# MCAN0_CFG register map
Vendor: Texas Instruments
Peripheral module from a debugger description file (folder J7VCL).
Registers are 32-bit, access per field, reset 0x0 unless marked. A register's access mark holds for its fields unless they carry their own. Offsets are as the file gives them; lines under a group give offsets from that group; [hi:lo] are bit positions; {n}, {i} and the like mark numbered series; 'fields as' and 'values as' point back to an identical list; <NAME> marks a mode.

## MCAN0_CFG (part 1 of 2)
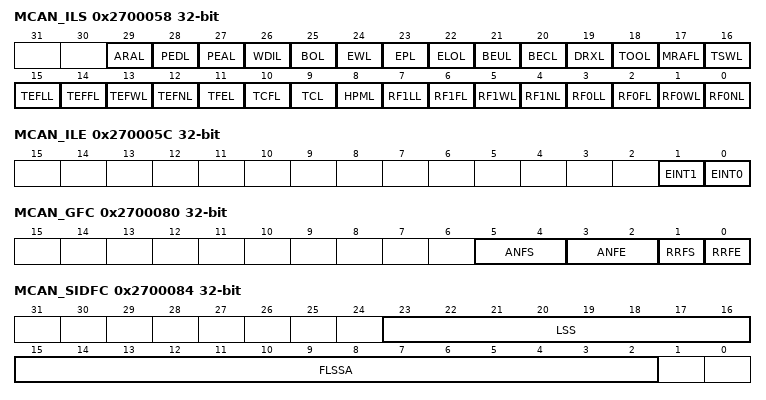
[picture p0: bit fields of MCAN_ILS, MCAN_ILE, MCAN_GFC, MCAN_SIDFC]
0x2700058 MCAN_ILS — Interrupt Line Select The Interrupt Line Select register assigns an interrupt generated by a specific interrupt flag from the register to one of the two module interrupt lines. For interrupt generation the respective interrupt line has to be enabled via the [0] EINT0 and [1] EINT1 bits.
  [29] ARAL rw — Access to Reserved Address Line 0h = Interrupt assigned to interrupt line INT0 1h = Interrupt assigned to interrupt line INT1
  [28] PEDL rw — Protocol Error in Data Phase Line 0h = Interrupt assigned to interrupt line INT0 1h = Interrupt assigned to interrupt line INT1
  [27] PEAL rw — Protocol Error in Arbitration Phase Line 0h = Interrupt assigned to interrupt line INT0 1h = Interrupt assigned to interrupt line INT1
  [26] WDIL rw — Watchdog Interrupt Line 0h = Interrupt assigned to interrupt line INT0 1h = Interrupt assigned to interrupt line INT1
  [25] BOL rw — Bus_Off Status Interrupt Line 0h = Interrupt assigned to interrupt line INT0 1h = Interrupt assigned to interrupt line INT1
  [24] EWL rw — Warning Status Interrupt Line 0h = Interrupt assigned to interrupt line INT0 1h = Interrupt assigned to interrupt line INT1
  [23] EPL rw — Error Passive Interrupt Line 0h = Interrupt assigned to interrupt line INT0 1h = Interrupt assigned to interrupt line INT1
  [22] ELOL rw — Error Logging Overflow Interrupt Line 0h = Interrupt assigned to interrupt line INT0 1h = Interrupt assigned to interrupt line INT1
  [21] BEUL rw — Bit Error Uncorrected Interrupt Line 0h = Interrupt assigned to interrupt line INT0 1h = Interrupt assigned to interrupt line INT1
  [20] BECL rw — Bit Error Corrected Interrupt Line 0h = Interrupt assigned to interrupt line INT0 1h = Interrupt assigned to interrupt line INT1
  [19] DRXL rw — Message stored to Dedicated Rx Buffer Interrupt Line 0h = Interrupt assigned to interrupt line INT0 1h = Interrupt assigned to interrupt line INT1
  [18] TOOL rw — Timeout Occurred Interrupt Line 0h = Interrupt assigned to interrupt line INT0 1h = Interrupt assigned to interrupt line INT1
  [17] MRAFL rw — Message RAM Access Failure Interrupt Line 0h = Interrupt assigned to interrupt line INT0 1h = Interrupt assigned to interrupt line INT1
  [16] TSWL rw — Timestamp Wraparound Interrupt Line 0h = Interrupt assigned to interrupt line INT0 1h = Interrupt assigned to interrupt line INT1
  [15] TEFLL rw — Tx Event FIFO Event Lost Interrupt Line 0h = Interrupt assigned to interrupt line INT0 1h = Interrupt assigned to interrupt line INT1
  [14] TEFFL rw — Tx Event FIFO Full Interrupt Line 0h = Interrupt assigned to interrupt line INT0 1h = Interrupt assigned to interrupt line INT1
  [13] TEFWL rw — Tx Event FIFO Watermark Reached Interrupt Line 0h = Interrupt assigned to interrupt line INT0 1h = Interrupt assigned to interrupt line INT1
  [12] TEFNL rw — Tx Event FIFO New Entry Interrupt Line 0h = Interrupt assigned to interrupt line INT0 1h = Interrupt assigned to interrupt line INT1
  [11] TFEL rw — Tx FIFO Empty Interrupt Line 0h = Interrupt assigned to interrupt line INT0 1h = Interrupt assigned to interrupt line INT1
  [10] TCFL rw — Transmission Cancellation Finished Interrupt Line 0h = Interrupt assigned to interrupt line INT0 1h = Interrupt assigned to interrupt line INT1
  [9] TCL rw — Transmission Completed Interrupt Line 0h = Interrupt assigned to interrupt line INT0 1h = Interrupt assigned to interrupt line INT1
  [8] HPML rw — High Priority Message Interrupt Line 0h = Interrupt assigned to interrupt line INT0 1h = Interrupt assigned to interrupt line INT1
  [7] RF1LL rw — Rx FIFO 1 Message Lost Interrupt Line 0h = Interrupt assigned to interrupt line INT0 1h = Interrupt assigned to interrupt line INT1
  [6] RF1FL rw — Rx FIFO 1 Full Interrupt Line 0h = Interrupt assigned to interrupt line INT0 1h = Interrupt assigned to interrupt line INT1
  [5] RF1WL rw — Rx FIFO 1 Watermark Reached Interrupt Line 0h = Interrupt assigned to interrupt line INT0 1h = Interrupt assigned to interrupt line INT1
  [4] RF1NL rw — Rx FIFO 1 New Message Interrupt Line 0h = Interrupt assigned to interrupt line INT0 1h = Interrupt assigned to interrupt line INT1
  [3] RF0LL rw — Rx FIFO 0 Message Lost Interrupt Line 0h = Interrupt assigned to interrupt line INT0 1h = Interrupt assigned to interrupt line INT1
  [2] RF0FL rw — Rx FIFO 0 Full Interrupt Line 0h = Interrupt assigned to interrupt line INT0 1h = Interrupt assigned to interrupt line INT1
  [1] RF0WL rw — Rx FIFO 0 Watermark Reached Interrupt Line 0h = Interrupt assigned to interrupt line INT0 1h = Interrupt assigned to interrupt line INT1
  [0] RF0NL rw — Rx FIFO 0 New Message Interrupt Line 0h = Interrupt assigned to interrupt line INT0 1h = Interrupt assigned to interrupt line INT1
0x270005C MCAN_ILE — Interrupt Line Enable Enable/disable interrupt lines INT0/INT1. Each of the two interrupt lines to the Host CPU can be enabled/disabled separately by programming the [0] EINT0 and [1] EINT1 bits.
  [1] EINT1 rw — Enable Interrupt Line 1 0h = Interrupt line INT1 disabled 1h = Interrupt line INT1 enabled
  [0] EINT0 rw — Enable Interrupt Line 0 0h = Interrupt line INT0 disabled 1h = Interrupt line INT0 enabled
0x2700080 MCAN_GFC — Global Filter Configuration Handling of non-matching frames and remote frames. Global settings for Message ID filtering. The register controls the filter path for standard and extended messages (see and ).
  [5:4] ANFS rw — Accept Non-matching Frames Standard Defines how received messages with 11-bit IDs that do not match any element of the filter list are treated. 0h = Accept in Rx FIFO 0 1h = Accept in Rx FIFO 1 2h = Reject 3h = Reject
  [3:2] ANFE rw — Accept Non-matching Frames Extended Defines how received messages with 29-bit IDs that do not match any element of the filter list are treated. 0h = Accept in Rx FIFO 0 1h = Accept in Rx FIFO 1 2h = Reject 3h = Reject
  [1] RRFS rw — Reject Remote Frames Standard 0h = Filter remote frames with 11-bit standard IDs 1h = Reject all remote frames with 11-bit standard IDs
  [0] RRFE rw — Reject Remote Frames Extended 0h = Filter remote frames with 29-bit extended IDs 1h = Reject all remote frames with 29-bit extended IDs
0x2700084 MCAN_SIDFC — Standard ID Filter Configuration Number of filter elements, pointer to start of filter list. Settings for 11-bit standard Message ID filtering. The Standard ID Filter Configuration controls the filter path for standard messages (see ).
  [23:16] LSS rw — List Size Standard 0h = No standard Message ID filter 1h-80h (1-128) = Number of standard Message ID filter elements &gt; 80h (128) = Values greater than 128 are interpreted as 128
  [15:2] FLSSA rw — Filter List Standard Start Address Start address of standard Message ID filter list (32-bit word address, see
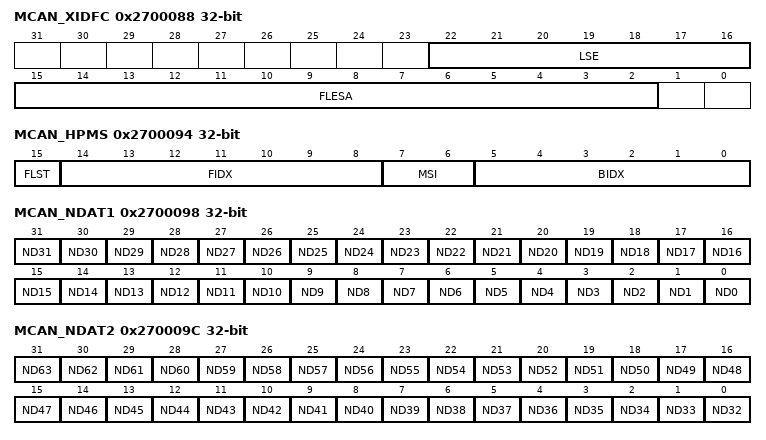
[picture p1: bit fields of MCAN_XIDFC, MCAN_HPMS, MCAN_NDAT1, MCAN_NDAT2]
0x2700088 MCAN_XIDFC — Extended ID Filter Configuration Number of filter elements, pointer to start of filter list. Settings for 29-bit extended Message ID filtering. The Extended ID Filter Configuration controls the filter path for standard messages (see ).
  [22:16] LSE rw — List Size Extended 0h = No extended Message ID filter 1h-40h (1-64) = Number of extended Message ID filter elements &gt; 40h (64) = Values greater than 64 are interpreted as 64
  [15:2] FLESA rw — Filter List Extended Start Address Start address of extended Message ID filter list (32-bit word address, see
0x2700090 MCAN_XIDAM reset 0x1FFFFFFF — Extended ID AND Mask 29-bit logical AND mask for J1939.
  [28:0] EIDM rw — Extended ID Mask For acceptance filtering of extended frames the Extended ID AND Mask is ANDed with the Message ID of a received frame. Intended for masking of 29-bit IDs in SAE J1939. With the reset value of all bits set to one the mask is not active.
0x2700094 MCAN_HPMS ro — High Priority Message Status Status monitoring of incoming high priority messages. This register is updated every time a Message ID filter element configured to generate a priority event matches. This can be used to monitor the status of incoming high priority messages and to enable fast access to these messages.
  [15] FLST — Filter List Indicates the filter list of the matching filter element. 0h = Standard Filter List 1h = Extended Filter List
  [14:8] FIDX — Filter Index Index of matching filter element. Range is 0 to
  [7:6] MSI — Message Storage Indicator 0h = No FIFO selected 1h = FIFO message lost 2h = Message stored in FIFO 0 3h = Message stored in FIFO 1
  [5:0] BIDX — Buffer Index Index of Rx FIFO element to which the message was stored. Only valid when the
0x2700098 MCAN_NDAT1 access not given — New Data 1 NewDat flags of dedicated Rx buffers 0-31. The register holds the New Data flags of Rx Buffers 0 to 31. The flags are set when the respective Rx Buffer has been updated from a received frame. The flags remain set until the Host CPU clears them. Aflag is cleared by writing a 1h to the corresponding bit position. Writing a 0h has no effect. A hard reset will clear the register.
  [n] ND{n} (n=0..31) — New Data 0h = Rx Buffer not updated 1h = Rx Buffer updated from new message (access RW1TC)
0x270009C MCAN_NDAT2 access not given — New Data 2 NewDat flags of dedicated Rx buffers 32-63. The register holds the New Data flags of Rx Buffers 32 to 63. The flags are set when the respective Rx Buffer has been updated from a received frame. The flags remain set until the Host CPU clears them. A flag is cleared by writing a 1h to the corresponding bit position. Writing a 0h has no effect. A hard reset will clear the register.
  [n-32] ND{n} (n=32..63) — New Data 0h = Rx Buffer not updated 1h = Rx Buffer updated from new message (access RW1TC)
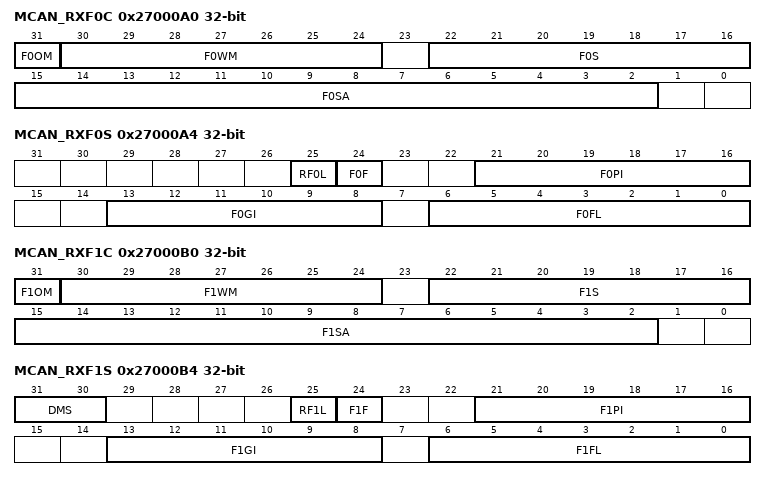
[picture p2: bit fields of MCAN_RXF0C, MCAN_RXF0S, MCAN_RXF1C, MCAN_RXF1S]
0x27000A0 MCAN_RXF0C — Rx FIFO 0 Configuration FIFO 0 operation mode, watermark, size and start address.
  [31] F0OM rw — FIFO 0 Operation Mode FIFO 0 can be operated in blocking or in overwrite mode (see 0h = FIFO 0 blocking mode 1h = FIFO 0 overwrite mode
  [30:24] F0WM rw — Rx FIFO 0 Watermark 0h = Watermark interrupt disabled 1h-40h (1-64) = Level for Rx FIFO 0 watermark interrupt ( &gt; 40h (64) = Watermark interrupt disabled
  [22:16] F0S rw — Rx FIFO 0 Size 0h = No Rx FIFO 0 1h-40h (1-64) = Number of Rx FIFO 0 elements &gt; 40h (64) = Values greater than 64 are interpreted as 64 The Rx FIFO 0 elements are indexed from 0 to
  [15:2] F0SA rw — Rx FIFO 0 Start Address Start address of Rx FIFO 0 in Message RAM (32-bit word address, see
0x27000A4 MCAN_RXF0S ro — Rx FIFO 0 Status FIFO 0 message lost/full indication, put index, get index and fill level.
  [25] RF0L — Rx FIFO 0 Message Lost This bit is a copy of interrupt flag 0h = No Rx FIFO 0 message lost 1h = Rx FIFO 0 message lost, also set after write attempt to Rx FIFO 0 of size zero Note:Overwriting the oldest message when the MCAN_RXF0C[31] F0OM = 1h will not set this flag.
  [24] F0F — Rx FIFO 0 Full 0h = Rx FIFO 0 not full 1h = Rx FIFO 0 full
  [21:16] F0PI — Rx FIFO 0 Put Index Rx FIFO 0 write index pointer, range 0 to 63.
  [13:8] F0GI — Rx FIFO 0 Get Index Rx FIFO 0 read index pointer, range 0 to 63.
  [6:0] F0FL — Rx FIFO 0 Fill Level Number of elements stored in Rx FIFO 0, range 0 to 64.
0x27000A8 MCAN_RXF0A — Rx FIFO 0 Acknowledge FIFO 0 acknowledge last index of read buffers, updates get index and fill level.
  [5:0] F0AI rw — Rx FIFO 0 Acknowledge Index After the Host CPU has read a message or a sequence of messages from Rx FIFO 0 it has to write the buffer index of the last element read from Rx FIFO 0 to the
0x27000AC MCAN_RXBC — Rx Buffer Configuration Start address of Rx buffer section.
  [15:2] RBSA rw — Rx Buffer Start Address Configures the start address of the Rx Buffers section in the Message RAM (32-bit word address, see ). Also used to reference debug messages A, B, C. Note:Debug feature is not supported.
0x27000B0 MCAN_RXF1C — Rx FIFO 1 Configuration FIFO 1 operation mode, watermark, size and start address.
  [31] F1OM rw — FIFO 1 Operation Mode FIFO 1 can be operated in blocking or in overwrite mode (see 0h = FIFO 1 blocking mode 1h = FIFO 1 overwrite mode
  [30:24] F1WM rw — Rx FIFO 1 Watermark 0h = Watermark interrupt disabled 1h-40h (1-64) = Level for Rx FIFO 1 watermark interrupt ( &gt; 40h (64) = Watermark interrupt disabled
  [22:16] F1S rw — Rx FIFO 1 Size 0h = No Rx FIFO 1 1h-40h (1-64) = Number of Rx FIFO 1 elements &gt; 40h (64) = Values greater than 64 are interpreted as 64 The Rx FIFO 1 elements are indexed from 0 to
  [15:2] F1SA rw — Rx FIFO 1 Start Address Start address of Rx FIFO 1 in Message RAM (32-bit word address, see
0x27000B4 MCAN_RXF1S ro — Rx FIFO 1 Status FIFO 1 message lost/full indication, put index, get index and fill level.
  [31:30] DMS — Debug Message Status 0h = Idle state, wait for reception of debug messages, DMA request is cleared 1h = Debug message A received 2h = Debug messages A, B received 3h = Debug messages A, B, C received, DMA request is set Note:Debug feature is not supported.
  [25] RF1L — Rx FIFO 1 Message Lost This bit is a copy of interrupt flag 0h = No Rx FIFO 1 message lost 1h = Rx FIFO 1 message lost, also set after write attempt to Rx FIFO 1 of size zero Note:Overwriting the oldest message when the MCAN_RXF1C[31] F1OM = 1h will not set this flag.
  [24] F1F — Rx FIFO 1 Full 0h = Rx FIFO 1 not full 1h = Rx FIFO 1 full
  [21:16] F1PI — Rx FIFO 1 Put Index Rx FIFO 1 write index pointer, range 0 to 63.
  [13:8] F1GI — Rx FIFO 1 Get Index Rx FIFO 1 read index pointer, range 0 to 63.
  [6:0] F1FL — Rx FIFO 1 Fill Level Number of elements stored in Rx FIFO 1, range 0 to 64.
0x27000B8 MCAN_RXF1A — Rx FIFO 1 Acknowledge FIFO 1 acknowledge last index of read buffers, updates get index and fill level.
  [5:0] F1AI rw — Rx FIFO 1 Acknowledge Index After the Host CPU has read a message or a sequence of messages from Rx FIFO 1 it has to write the buffer index of the last element read from Rx FIFO 1 to the
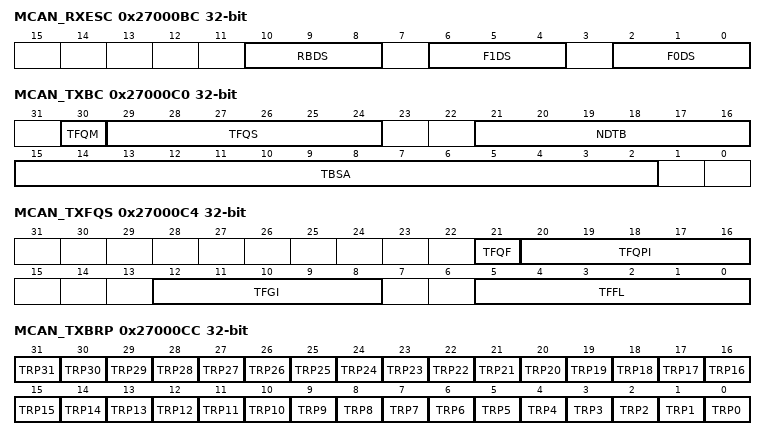
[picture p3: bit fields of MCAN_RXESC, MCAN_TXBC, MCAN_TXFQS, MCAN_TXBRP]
0x27000BC MCAN_RXESC — Rx Buffer/FIFO Element Size Configuration Configure data field size for storage of accepted frames.
  [10:8] RBDS rw — Rx Buffer Data Field Size 0h = 8 byte data field 1h = 12 byte data field 2h = 16 byte data field 3h = 20 byte data field 4h = 24 byte data field 5h = 32 byte data field 6h = 48 byte data field 7h = 64 byte data field
  [6:4] F1DS rw — Rx FIFO 1 Data Field Size 0h = 8 byte data field 1h = 12 byte data field 2h = 16 byte data field 3h = 20 byte data field 4h = 24 byte data field 5h = 32 byte data field 6h = 48 byte data field 7h = 64 byte data field
  [2:0] F0DS rw — Rx FIFO 0 Data Field Size 0h = 8 byte data field 1h = 12 byte data field 2h = 16 byte data field 3h = 20 byte data field 4h = 24 byte data field 5h = 32 byte data field 6h = 48 byte data field 7h = 64 byte data field Note:In case the data field size of an accepted CAN frame exceeds the data field size configured for the matching Rx Buffer or Rx FIFO, only the number of bytes as configured by the MCAN_RXESC register are stored to the Rx Buffer respectively Rx FIFO element. The rest of the frame's data field is ignored.
0x27000C0 MCAN_TXBC — Tx Buffer Configuration Configure Tx FIFO/Queue mode, Tx FIFO/Queue size, number of dedicated Tx buffers, Tx buffer start address.
  [30] TFQM rw — Tx FIFO/Queue Mode 0h = Tx FIFO operation 1h = Tx Queue operation
  [29:24] TFQS rw — Transmit FIFO/Queue Size 0h = No Tx FIFO/Queue 1h-20h (1-32) = Number of Tx Buffers used for Tx FIFO/Queue &gt; 20h (32) = Values greater than 32 are interpreted as 32
  [21:16] NDTB rw — Number of Dedicated Transmit Buffers 0h = No Dedicated Tx Buffers 1h-20h (1-32) = Number of Dedicated Tx Buffers &gt; 20h (32) = Values greater than 32 are interpreted as 32
  [15:2] TBSA rw — Tx Buffers Start Address Start address of Tx Buffers section in Message RAM (32-bit word address, see Note:Be aware that the sum of the MCAN_TXBC[29-24] TFQS and MCAN_TXBC[21-16] NDTB fields may be not greater than 32. There is no check for erroneous configurations. The Tx Buffers section in the Message RAM starts with the dedicated Tx Buffers.
0x27000C4 MCAN_TXFQS ro — Tx FIFO/Queue Status Tx FIFO/Queue full indication and put index, Tx FIFO get index and fill level. The Tx FIFO/Queue status is related to the pending Tx requests listed in the register. Therefore the effect of Add/Cancellation requests may be delayed due to a running Tx scan (the register not yet updated).
  [21] TFQF — Tx FIFO/Queue Full 0h = Tx FIFO/Queue not full 1h = Tx FIFO/Queue full
  [20:16] TFQPI — Tx FIFO/Queue Put Index Tx FIFO/Queue write index pointer, range 0 to 31.
  [12:8] TFGI — Tx FIFO Get Index Tx FIFO read index pointer, range 0 to 31. Read as zero when Tx Queue operation is configured (
  [5:0] TFFL — Tx FIFO Free Level Number of consecutive free Tx FIFO elements starting from the Note:In case of mixed configurations where dedicated Tx Buffers are combined with a Tx FIFO or a Tx Queue, the Put and Get Indices indicate the number of the Tx Buffer starting with the first dedicated Tx Buffers.
0x27000C8 MCAN_TXESC — Tx Buffer Element Size Configuration Configure data field size for frame transmission. Configures the number of data bytes belonging to a Tx Buffer element. Data field sizes > 8 bytes are intended for CAN FD operation only.
  [2:0] TBDS rw — Tx Buffer Data Field Size 0h = 8 byte data field 1h = 12 byte data field 2h = 16 byte data field 3h = 20 byte data field 4h = 24 byte data field 5h = 32 byte data field 6h = 48 byte data field 7h = 64 byte data field Note:In case the data length code DLC of a Tx Buffer element is configured to a value higher than the Tx Buffer data field size MCAN_TXESC[2-0] TBDS, the bytes not defined by the Tx Buffer are transmitted as CCh (padding bytes).
0x27000CC MCAN_TXBRP ro — Tx Buffer Request Pending Tx buffers with pending transmission request. Each Tx Buffer has its own Transmission Request Pending bit. The bits are set via the register. The bits are reset after a requested transmission has completed or has been cancelled via the register. The bits are set only for those Tx Buffers configured via the register. After a bit has been set, a Tx scan (see , Tx Handling) is started to check for the pending Tx request with the highest priority (Tx Buffer with lowest Message ID). A cancellation request resets the corresponding transmission request pending bit of register the register. In case a transmission has already been started when a cancellation is requested, this is done at the end of the transmission, regardless whether the transmission was successful or not. The cancellation request bits are reset directly after the corresponding bit has been reset. After a cancellation has been requested, a finished cancellation is signalled via the flag • after successful transmission together with the corresponding bit • when the transmission has not yet been started at the point of cancellation • when the transmission has been aborted due to lost arbitration • when an error occurred during frame transmission In DAR mode all transmissions are automatically cancelled if they are not successful. The corresponding bit is set for all unsuccessful transmissions. Note: The bits which are set while a Tx scan is in progress are not considered during this particular Tx scan. In case a cancellation is requested for such a Tx Buffer, this Add Request is cancelled immediately, the corresponding bit is reset.
  [n] TRP{n} (n=0..31) — Transmission Request Pending 0h = No transmission request pending 1h = Transmission request pending
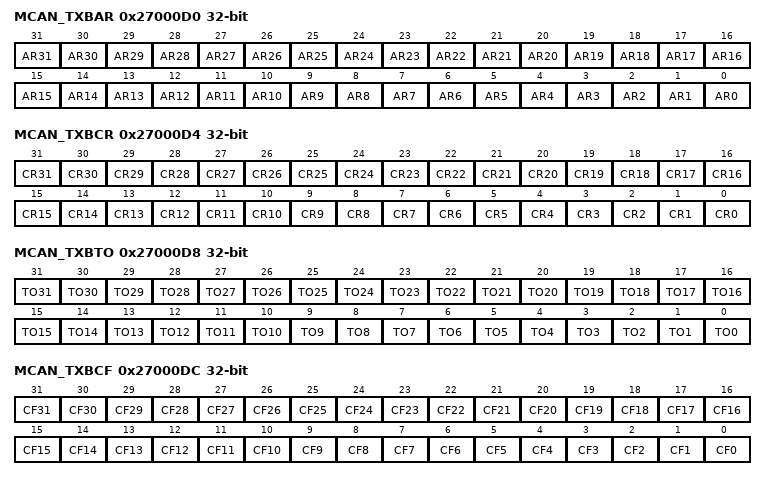
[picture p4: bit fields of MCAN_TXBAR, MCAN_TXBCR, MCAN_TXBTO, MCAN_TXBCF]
0x27000D0 MCAN_TXBAR access not given — Tx Buffer Add Request Add transmission requests. Each Tx Buffer has its own Add Request bit. Writing 1h will set the corresponding Add Request bit; writing a 0h has no impact. This enables the Host CPU to set transmission requests for multiple Tx Buffers with one write to the register. The bits are set only for those Tx Buffers configured via the register. When no Tx scan is running, the bits are reset immediately, else the bits remain set until the Tx scan process has completed. Note: If an add request is applied for a Tx Buffer with pending transmission request (corresponding bit already set), this add request is ignored.
  [n] AR{n} (n=0..31) — Add Request 0h = No transmission request added 1h = Transmission requested added (access RW1TC)
0x27000D4 MCAN_TXBCR access not given — Tx Buffer Cancellation Request Request cancellation of pending transmissions. Each Tx Buffer has its own Cancellation Request bit. Writing a 1h will set the corresponding Cancellation Request bit; writing a 0h has no impact. This enables the Host CPU to set cancellation requests for multiple Tx Buffers with one write to the register. The bits are set only for those Tx Buffers configured via the register. The bits remain set until the corresponding bit of the register is reset.
  [n] CR{n} (n=0..31) — Cancellation Request 0h = No cancellation pending 1h = Cancellation pending (access RW1TC)
0x27000D8 MCAN_TXBTO ro — Tx Buffer Transmission Occurred Signals successful transmissions, set when corresponding flag is cleared. Each Tx Buffer has its own Transmission Occurred bit. The bits are set when the corresponding bit is cleared after a successful transmission. The bits are reset when a new transmission is requested by writing a 1h to the corresponding bit of register the register.
  [n] TO{n} (n=0..31) — Transmission Occurred 0h = No transmission occurred 1h = Transmission occurred
0x27000DC MCAN_TXBCF ro — Tx Buffer Cancellation Finished Signals successful transmit cancellation, set when corresponding flag is cleared after cancellation request. Each Tx Buffer has its own Cancellation Finished bit. The bits are set when the corresponding bit is cleared after a cancellation was requested via the register. In case the corresponding bit was not set at the point of cancellation, [n] CF bit is set immediately. The bits are reset when a new transmission is requested by writing a 1h to the corresponding bit of the register.
  [n] CF{n} (n=0..31) — Cancellation Finished 0h = No transmit buffer cancellation 1h = Transmit buffer cancellation finished
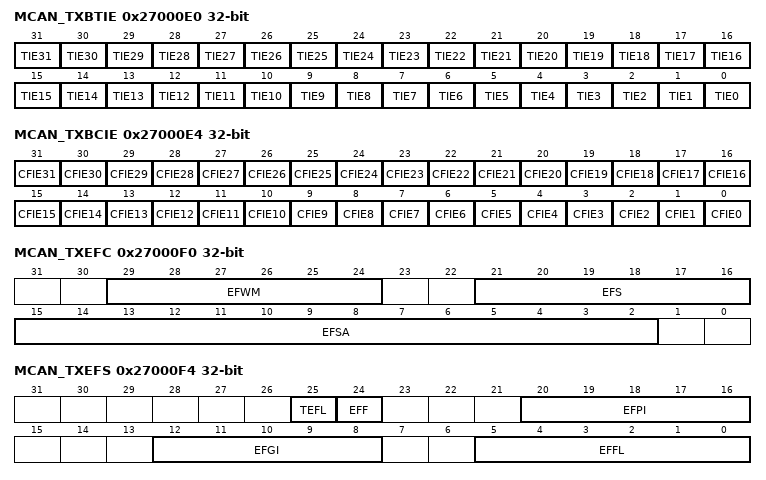
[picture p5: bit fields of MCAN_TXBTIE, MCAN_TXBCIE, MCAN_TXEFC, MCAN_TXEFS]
0x27000E0 MCAN_TXBTIE rw — Tx Buffer Transmission Interrupt Enable Enable transmit interrupts for selected Tx buffers.
  [n] TIE{n} (n=0..31) — Transmission Interrupt Enable 0h = Transmission interrupt disabled 1h = Transmission interrupt enable
0x27000E4 MCAN_TXBCIE rw — Tx Buffer Cancellation Finished Interrupt Enable Enable cancellation finished interrupts for selected Tx buffers.
  [n] CFIE{n} (n=0..31) — Cancellation Finished Interrupt Enable 0h = Cancellation finished interrupt disabled 1h = Cancellation finished interrupt enabled
0x27000F0 MCAN_TXEFC — Tx Event FIFO Configuration Tx event FIFO watermark, size and start address.
  [29:24] EFWM rw — Event FIFO Watermark 0h = Watermark interrupt disabled 1h-20h (1-32) = Level for Tx Event FIFO watermark interrupt ( &gt; 20h (32) = Watermark interrupt disabled
  [21:16] EFS rw — Event FIFO Size 0h = Tx Event FIFO disabled 1h-20h (1-32) = Number of Tx Event FIFO elements &gt; 20h (32) = Values greater than 32 are interpreted as 32 The Tx Event FIFO elements are indexed from 0 to
  [15:2] EFSA rw — Event FIFO Start Address Start address of Tx Event FIFO in Message RAM (32-bit word address, see
0x27000F4 MCAN_TXEFS ro — Tx Event FIFO Status Tx event FIFO element lost/full indication, put index, get index, and fill level.
  [25] TEFL — This bit is a copy of interrupt flag 0h = No Tx Event FIFO element lost 1h = Tx Event FIFO element lost, also set after write attempt to Tx Event FIFO of size zero.
  [24] EFF — Event FIFO Full 0h = Tx Event FIFO not full 1h = Tx Event FIFO full
  [20:16] EFPI — Event FIFO Put Index Tx Event FIFO write index pointer, range 0 to 31.
  [12:8] EFGI — Event FIFO Get Index Tx Event FIFO read index pointer, range 0 to 31.
  [5:0] EFFL — Event FIFO Fill Level Number of elements stored in Tx Event FIFO, range 0 to 32.
0x27000F8 MCAN_TXEFA — Tx Event FIFO Acknowledge Tx event FIFO acknowledge last index of read elements, updates get index and fill level.
  [4:0] EFAI rw — After the Host CPU has read an element or a sequence of elements from the Tx Event FIFO it has to write the index of the last element read from Tx Event FIFO to the
